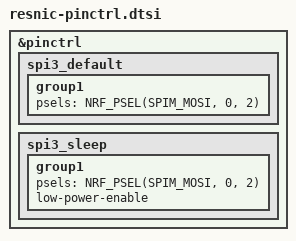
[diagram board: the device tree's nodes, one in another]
#include <dt-bindings/pinctrl/nrf-pinctrl.h>

&pinctrl {
	spi3_default: spi3_default {
		group1 {
			psels = <NRF_PSEL(SPIM_MOSI, 0, 2)>;
		};
	};

	spi3_sleep: spi3_sleep {
		group1 {
			psels = <NRF_PSEL(SPIM_MOSI, 0, 2)>;
			low-power-enable;
		};
	};
};
